# MINI51AN_v1 register map
File version: 1.0
Registers are 32-bit, read-write, reset 0x0 unless marked. A register's access mark holds for its fields unless they carry their own. Offsets are from the block's base; [hi:lo] are bit positions; lines under a group give offsets from that group; {n}, {i} and the like mark numbered series.

## SCS — SCS Register Map
Base 0xE000E000
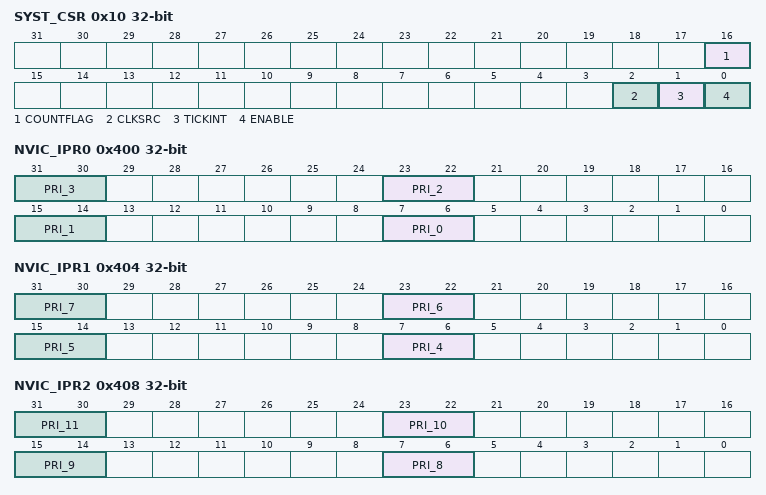
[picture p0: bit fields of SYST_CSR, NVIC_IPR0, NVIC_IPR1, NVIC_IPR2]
0x10 SYST_CSR — SysTick Control and Status
  [16] COUNTFLAG — Returns 1 if timer counted to 0 since this register was read last time. COUNTFLAG is set by a count transition from 1 to 0. COUNTFLAG is cleared on read or by a write to the Current Value register.
  [2] CLKSRC
    0=Clock source is optional (refer to STCLK_S); 1=Core clock used for SysTick if no external clock provided; this bit will read as 1 and ignore writes
  [1] TICKINT
    0=Counting down to 0 does not cause the SysTick exception to be pended. Software can use COUNTFLAG to determine if a count to zero has occurred; 1=Counting down to 0 will cause the SysTick exception to be pended. Clearing the SysTick Current Value register by a register write in software will not cause SysTick to be pended
  [0] ENABLE
    0=The counter Disabled; 1=The counter will operate in a multi-shot manner
0x14 SYST_RVR (reset mask 0xFF000000) — SysTick Reload Value Register
  [23:0] RELOAD — Value to load into the Current Value register when the counter reaches 0.
0x18 SYST_CVR (reset mask 0xFF000000) — SysTick Current Value Register
  [23:0] CURRENT — Current counter value. This is the value of the counter at the time it is sampled. The counter does not provide read-modify-write protection. The register is write-clear. Software write of any value will clear the register to 0. Bits RAZ is not supported (see SysTick Reload Value Register).
0x100 NVIC_ISER — IRQ0 ~ IRQ31 Set-enable Control Register
  [31:0] SETENA — Enable one or more interrupts within a group of 32 bits. Each bit represents an interrupt number from IRQ0 ~ IRQ31 (Vector number from 16 ~ 47). The register reads back with the current enable state.
    0=No effect; 1=The associated interrupt Enabled
0x180 NVIC_ICER — IRQ0 ~ IRQ31 Clear-enable Control Register
  [31:0] CLRENA — Disable one or more interrupts within a group of 32. Each bit represents an interrupt number from IRQ0 ~ IRQ31 (Vector number from 16 ~ 47). The register reads back with the current enable state.
    0=No effect; 1=The associated interrupt Disabled
0x200 NVIC_ISPR — IRQ0 ~ IRQ31 Set-pending Control Register
  [31:0] SETPEND — The register reads back with the current pending state.
    0=No effect; 1=The associated interrupt under software control pended. Each bit represents an interrupt number from IRQ0 ~ IRQ31 (Vector number from 16 ~ 47)
0x280 NVIC_ICPR — IRQ0 ~ IRQ31 Clear-pending Control Register
  [31:0] CLRPEND — The register reads back with the current pending state.
    0=No effect; 1=The associated interrupt under software control un-pended. Each bit represents an interrupt number from IRQ0 ~ IRQ31 (Vector number from 16 ~ 47)
0x400 NVIC_IPR0 — IRQ0 ~ IRQ3 Priority Control Register
  [8n+7:8n+6] PRI_{n} (n=0..3) — Priority of IRQ{n}. 0 denotes the highest priority and 3 denotes the lowest priority.
0x404 NVIC_IPR1 — IRQ4 ~ IRQ7 Priority Control Register
  [8n-25:8n-26] PRI_{n} (n=4..7) — Priority of IRQ{n}. 0 denotes the highest priority and 3 denotes the lowest priority.
0x408 NVIC_IPR2 — IRQ8 ~ IRQ11 Priority Control Register
  [8n-57:8n-58] PRI_{n} (n=8..11) — Priority of IRQ{n}. 0 denotes the highest priority and 3 denotes the lowest priority.
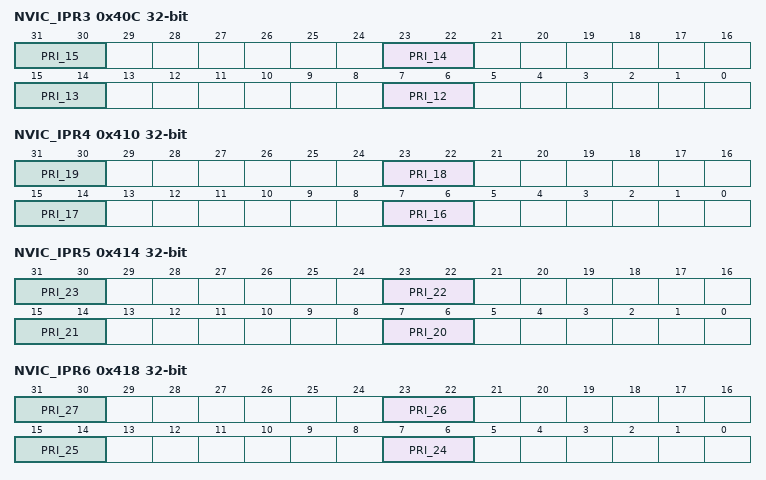
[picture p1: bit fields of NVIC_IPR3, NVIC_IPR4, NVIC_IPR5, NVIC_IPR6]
0x40C NVIC_IPR3 — IRQ12 ~ IRQ15 Priority Control Register
  [8n-89:8n-90] PRI_{n} (n=12..15) — Priority of IRQ{n}. 0 denotes the highest priority and 3 denotes the lowest priority.
0x410 NVIC_IPR4 — IRQ16 ~ IRQ19 Priority Control Register
  [8n-121:8n-122] PRI_{n} (n=16..19) — Priority of IRQ{n}. 0 denotes the highest priority and 3 denotes the lowest priority.
0x414 NVIC_IPR5 — IRQ20 ~ IRQ23 Priority Control Register
  [8n-153:8n-154] PRI_{n} (n=20..23) — Priority of IRQ{n}. 0 denotes the highest priority and 3 denotes the lowest priority.
0x418 NVIC_IPR6 — IRQ24 ~ IRQ27 Priority Control Register
  [8n-185:8n-186] PRI_{n} (n=24..27) — Priority of IRQ{n}. 0 denotes the highest priority and 3 denotes the lowest priority.
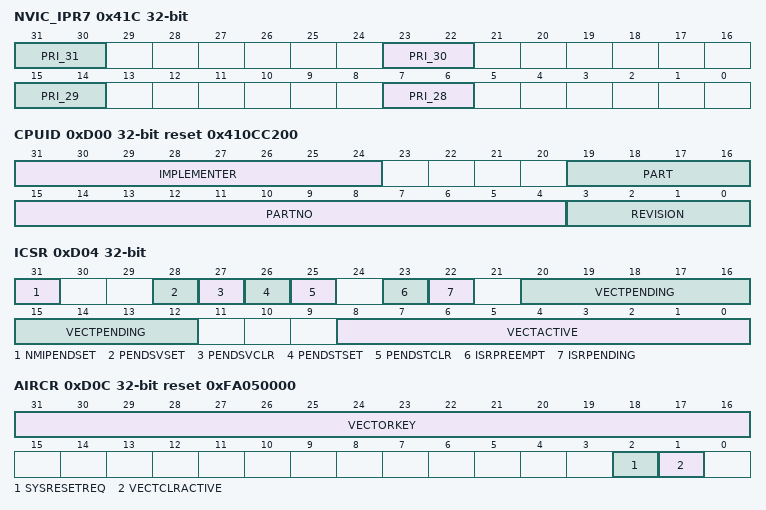
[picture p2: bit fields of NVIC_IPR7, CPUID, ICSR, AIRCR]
0x41C NVIC_IPR7 — IRQ28 ~ IRQ31 Priority Control Register
  [8n-217:8n-218] PRI_{n} (n=28..31) — Priority of IRQ{n}. 0 denotes the highest priority and 3 denotes the lowest priority.
0xD00 CPUID ro reset 0x410CC200 — CPUID Base Register
  [31:24] IMPLEMENTER
  [19:16] PART — Reads as 0xC for ARMv6-M parts.
  [15:4] PARTNO — Reads as 0xC20.
  [3:0] REVISION — Reads as 0x0.
0xD04 ICSR — Interrupt Control State Register
  [31] NMIPENDSET — NMI Set-pending Bit. Write: Because NMI is the highest-priority exception, normally the processor enters the NMI exception handler as soon as it detects a write of 1 to this bit. Entering the handler clears this bit to 0. This means a read of this bit by the NMI exception handler returns 1 only if the NMI signal is reasserted while the processor is executing that handler.
    0=No effect. NMI exception not pending; 1=NMI exception state changed to pending. NMI exception pending
  [28] PENDSVSET — PendSV Set-pending Bit. Write: Writing 1 to this bit is the only way to set the PendSV exception state to pending.
    0=No effect. PendSV exception not pending; 1=PendSV exception state changed to pending. PendSV exception pending
  [27] PENDSVCLR wo — PendSV Clear-pending Bit (Write Only). Write:
    0=No effect; 1=The pending state removed from the PendSV exception
  [26] PENDSTSET — SysTick Exception Set-pending Bit. Write:
    0=No effect. SysTick exception not pending; 1=SysTick exception state changed to pending. SysTick exception pending
  [25] PENDSTCLR wo — SysTick Exception Clear-pending Bit (Write Only). Write:
    0=No effect; 1=The pending state removed from the SysTick exception
  [23] ISRPREEMPT ro — Interrupt Preemption (Read Only). If set, a pending exception will be serviced on exit from the debug halt state.
  [22] ISRPENDING ro — Interrupt Pending Flag (Read Only). Excluding NMI and Faults.
    0=Interrupt not pending; 1=Interrupt pending
  [20:12] VECTPENDING ro — Vector Pending Indicator (Read Only). This field indicates the exception number of the highest priority pending enabled exception:
    0=No pending exceptions
  [8:0] VECTACTIVE ro — Vector Active Indicator (Read Only). This field contains the active exception number:
    0=Thread mode
0xD0C AIRCR reset 0xFA050000 — Application Interrupt and Reset Control Register
  [31:16] VECTORKEY — When writing this register, this field should be 0x05FA; otherwise, the write action will be unpredictable.
  [2] SYSRESETREQ — Writing this bit 1 will cause a reset signal to be asserted to the chip to indicate a reset is requested. The bit is a write only bit and self-clears as part of the reset sequence.
  [1] VECTCLRACTIVE — Setting this bit to 1 will clear all active state information for fixed and configurable exceptions. The bit is a write only bit and can only be written when the core is halted. Note: It is the debugger's responsibility to re-initialize the stack.
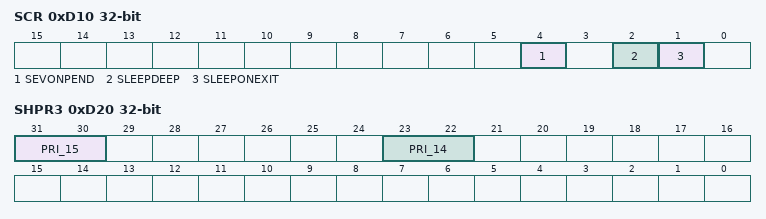
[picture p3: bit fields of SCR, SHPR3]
0xD10 SCR — System Control Register
  [4] SEVONPEND — Send Event on Pending Bit. When an event or interrupt enters pending state, the event signal wakes up the processor from WFE. If the processor is not waiting for an event, the event is registered and affects next WFE. The processor also wakes up on execution of an SEV instruction or an external event.
    0=Only the enabled interrupts or events can wake up the processor, disabled interrupts are excluded; 1=The enabled events and all interrupts, including disabled interrupts, can wake up the processor
  [2] SLEEPDEEP — Deep Sleep Mode Enable. This bit controls whether the processor uses sleep or deep sleep as its low power mode:
    0=Sleep; 1=Deep sleep
  [1] SLEEPONEXIT — Sleep-On-exit Enable. This bit controls sleep-on-exit when returning from Handler mode to Thread mode: Setting this bit to 1 enables an interrupt driven application to avoid returning to an empty main application.
    0=Do not sleep when returning to Thread mode; 1=Enter sleep or deep sleep when returning from an ISR to Thread mode
0xD1C SHPR2 — System Handler Priority Register 2
  [31:30] PRI_11 — Priority of System Handler 11 - SVCall. 0 denotes the highest priority and 3 denotes lowest priority.
0xD20 SHPR3 — System Handler Priority Register 3
  [31:30] PRI_15 — Priority of System Handler 15 - SysTick. 0 denotes the highest priority and 3 denotes lowest priority.
  [23:22] PRI_14 — Priority of System Handler 14 - PendSV. 0 denotes the highest priority and 3 denotes lowest priority.
